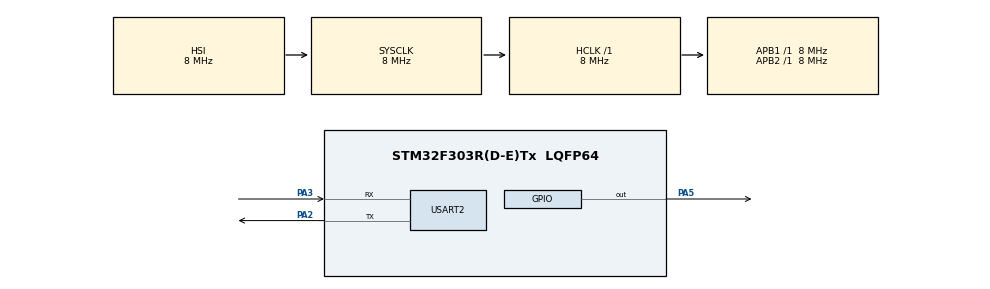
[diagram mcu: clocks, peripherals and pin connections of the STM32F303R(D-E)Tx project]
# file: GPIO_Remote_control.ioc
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Mcu.Family=STM32F3
Mcu.Name=STM32F303R(D-E)Tx
Mcu.Package=LQFP64
NVIC.PriorityGroup=NVIC_PRIORITYGROUP_4
NVIC.USART2_IRQn=true\:0\:0\:false\:false\:true\:true\:true\:true
PA2.Mode=Asynchronous
PA2.Signal=USART2_TX
PA3.Mode=Asynchronous
PA3.Signal=USART2_RX
PA5.Signal=GPIO_Output
ProjectManager.HeapSize=0x200
ProjectManager.StackSize=0x400
ProjectManager.TargetToolchain=STM32CubeIDE
RCC.AHBFreq_Value=8000000
RCC.APB1Freq_Value=8000000
RCC.APB2Freq_Value=8000000
RCC.CortexFreq_Value=8000000
RCC.HSE_VALUE=8000000
RCC.HSI_VALUE=8000000
RCC.LSE_VALUE=32768
RCC.SYSCLKFreq_VALUE=8000000
RCC.USBFreq_Value=16000000
USART2.VirtualMode-Asynchronous=VM_ASYNC
board=custom

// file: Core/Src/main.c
/* USER CODE BEGIN Header */
/**
  ******************************************************************************
  * @file           : main.c
  * @brief          : Main program body
  ******************************************************************************
  * @attention
  *
  * Copyright (c) 2025 STMicroelectronics.
  * All rights reserved.
  *
  * This software is licensed under terms that can be found in the LICENSE file
  * in the root directory of this software component.
  * If no LICENSE file comes with this software, it is provided AS-IS.
  *
  ******************************************************************************
  */
/* USER CODE END Header */
#include "main.h"

/* USER CODE BEGIN Includes */
#include <string.h>
#include <stdio.h>
/* USER CODE END Includes */

UART_HandleTypeDef huart2;

/* USER CODE BEGIN PV */
char cmdBuffer[20];  // command buffer
uint8_t rxByte;      // one byte receive buffer for interrupt
uint8_t idx = 0;     // index in cmdBuffer
volatile uint8_t commandReceivedFlag = 0; // Flag to signal main loop that a command is ready
/* USER CODE END PV */

void SystemClock_Config(void);
static void MX_GPIO_Init(void);
static void MX_USART2_UART_Init(void);
/* USER CODE BEGIN PFP */
void ProcessCommand(void);
/* USER CODE END PFP */

/* USER CODE BEGIN 0 */
void HAL_UART_RxCpltCallback(UART_HandleTypeDef *huart) {
    if (huart->Instance == USART2) {
        // Echo received byte back (optional, for debugging)
        // HAL_UART_Transmit(&huart2, &rxByte, 1, HAL_MAX_DELAY);

        if (rxByte != '\n' && idx < sizeof(cmdBuffer) - 1) {
            cmdBuffer[idx++] = rxByte;
        } else {
            // Null-terminate the string
            cmdBuffer[idx] = '\0';
            // Set flag to process command in main loop
            commandReceivedFlag = 1;
            idx = 0; // Reset index for next command
        }
        // Re-enable UART receive interrupt for the next byte
        HAL_UART_Receive_IT(&huart2, &rxByte, 1);
    }
}

void ProcessCommand(void) {
    HAL_UART_Transmit(&huart2, (uint8_t *)"Got: ", 5, HAL_MAX_DELAY);
    HAL_UART_Transmit(&huart2, (uint8_t *)cmdBuffer, strlen(cmdBuffer), HAL_MAX_DELAY);
    HAL_UART_Transmit(&huart2, (uint8_t *)"\r\n", 2, HAL_MAX_DELAY);

    // Command handling for GPIO 26 (PA5)
    if (strcmp(cmdBuffer, "26 ON") == 0) {
        HAL_GPIO_WritePin(GPIOA, GPIO_PIN_5, GPIO_PIN_SET);
        HAL_UART_Transmit(&huart2, (uint8_t *)"GPIO A5 (26) is ON\r\n", strlen("GPIO A5 (26) is ON\r\n"), HAL_MAX_DELAY);
    } else if (strcmp(cmdBuffer, "26 OFF") == 0) {
        HAL_GPIO_WritePin(GPIOA, GPIO_PIN_5, GPIO_PIN_RESET);
        HAL_UART_Transmit(&huart2, (uint8_t *)"GPIO A5 (26) is OFF\r\n", strlen("GPIO A5 (26) is OFF\r\n"), HAL_MAX_DELAY);
    }
    // Command handling for GPIO 27 (e.g., PA6 - adjust if different)
//    else if (strcmp(cmdBuffer, "27 ON") == 0) {
//        HAL_GPIO_WritePin(GPIO_27_PORT, GPIO_27_PIN, GPIO_PIN_SET); // Assuming PA6 for GPIO 27
//        HAL_UART_Transmit(&huart2, (uint8_t *)"GPIO A6 (27) is ON\r\n", strlen("GPIO A6 (27) is ON\r\n"), HAL_MAX_DELAY);
//    } else if (strcmp(cmdBuffer, "27 OFF") == 0) {
//        HAL_GPIO_WritePin(GPIO_27_PORT, GPIO_27_PIN, GPIO_PIN_RESET); // Assuming PA6 for GPIO 27
//        HAL_UART_Transmit(&huart2, (uint8_t *)"GPIO A6 (27) is OFF\r\n", strlen("GPIO A6 (27) is OFF\r\n"), HAL_MAX_DELAY);
//    }
    else {
        HAL_UART_Transmit(&huart2, (uint8_t *)"Unknown command\r\n", strlen("Unknown command\r\n"), HAL_MAX_DELAY);
    }
}
/* USER CODE END 0 */

int main(void)
{

  /* MCU Configuration--------------------------------------------------------*/

  /* Reset of all peripherals, Initializes the Flash interface and the Systick. */
  HAL_Init();

  /* Configure the system clock */
  SystemClock_Config();

  /* Initialize all configured peripherals */
  MX_GPIO_Init();
  MX_USART2_UART_Init();
  /* USER CODE BEGIN 2 */
  HAL_UART_Receive_IT(&huart2, &rxByte, 1);
    HAL_UART_Transmit(&huart2, (uint8_t *)"STM32 UART Ready. Waiting for commands...\r\n", strlen("STM32 UART Ready. Waiting for commands...\r\n"), HAL_MAX_DELAY);
  /* USER CODE END 2 */

  /* Infinite loop */
  while (1)
  {
	  if (commandReceivedFlag) {
	          commandReceivedFlag = 0; // Clear the flag
	          ProcessCommand();        // Process the command
	      }
	      }
  }

void SystemClock_Config(void)
{
  RCC_OscInitTypeDef RCC_OscInitStruct = {0};
  RCC_ClkInitTypeDef RCC_ClkInitStruct = {0};
  RCC_PeriphCLKInitTypeDef PeriphClkInit = {0};

  /** Initializes the RCC Oscillators according to the specified parameters
  * in the RCC_OscInitTypeDef structure.
  */
  RCC_OscInitStruct.OscillatorType = RCC_OSCILLATORTYPE_HSI;
  RCC_OscInitStruct.HSIState = RCC_HSI_ON;
  RCC_OscInitStruct.HSICalibrationValue = RCC_HSICALIBRATION_DEFAULT;
  RCC_OscInitStruct.PLL.PLLState = RCC_PLL_NONE;
  if (HAL_RCC_OscConfig(&RCC_OscInitStruct) != HAL_OK)
  {
    Error_Handler();
  }

  /** Initializes the CPU, AHB and APB buses clocks
  */
  RCC_ClkInitStruct.ClockType = RCC_CLOCKTYPE_HCLK|RCC_CLOCKTYPE_SYSCLK
                              |RCC_CLOCKTYPE_PCLK1|RCC_CLOCKTYPE_PCLK2;
  RCC_ClkInitStruct.SYSCLKSource = RCC_SYSCLKSOURCE_HSI;
  RCC_ClkInitStruct.AHBCLKDivider = RCC_SYSCLK_DIV1;
  RCC_ClkInitStruct.APB1CLKDivider = RCC_HCLK_DIV1;
  RCC_ClkInitStruct.APB2CLKDivider = RCC_HCLK_DIV1;

  if (HAL_RCC_ClockConfig(&RCC_ClkInitStruct, FLASH_LATENCY_0) != HAL_OK)
  {
    Error_Handler();
  }
  PeriphClkInit.PeriphClockSelection = RCC_PERIPHCLK_USART2;
  PeriphClkInit.Usart2ClockSelection = RCC_USART2CLKSOURCE_PCLK1;
  if (HAL_RCCEx_PeriphCLKConfig(&PeriphClkInit) != HAL_OK)
  {
    Error_Handler();
  }
}

static void MX_USART2_UART_Init(void)
{

  huart2.Instance = USART2;
  huart2.Init.BaudRate = 115200;
  huart2.Init.WordLength = UART_WORDLENGTH_8B;
  huart2.Init.StopBits = UART_STOPBITS_1;
  huart2.Init.Parity = UART_PARITY_NONE;
  huart2.Init.Mode = UART_MODE_TX_RX;
  huart2.Init.HwFlowCtl = UART_HWCONTROL_NONE;
  huart2.Init.OverSampling = UART_OVERSAMPLING_16;
  huart2.Init.OneBitSampling = UART_ONE_BIT_SAMPLE_DISABLE;
  huart2.AdvancedInit.AdvFeatureInit = UART_ADVFEATURE_NO_INIT;
  if (HAL_UART_Init(&huart2) != HAL_OK)
  {
    Error_Handler();
  }

}

static void MX_GPIO_Init(void)
{
  GPIO_InitTypeDef GPIO_InitStruct = {0};

  /* GPIO Ports Clock Enable */
  __HAL_RCC_GPIOA_CLK_ENABLE();

  /*Configure GPIO pin Output Level */
  HAL_GPIO_WritePin(GPIOA, GPIO_PIN_5, GPIO_PIN_RESET);

  /*Configure GPIO pin : PA5 */
  GPIO_InitStruct.Pin = GPIO_PIN_5;
  GPIO_InitStruct.Mode = GPIO_MODE_OUTPUT_PP;
  GPIO_InitStruct.Pull = GPIO_NOPULL;
  GPIO_InitStruct.Speed = GPIO_SPEED_FREQ_LOW;
  HAL_GPIO_Init(GPIOA, &GPIO_InitStruct);

}

void Error_Handler(void)
{
  __disable_irq();
  while (1)
  {
  }
}
